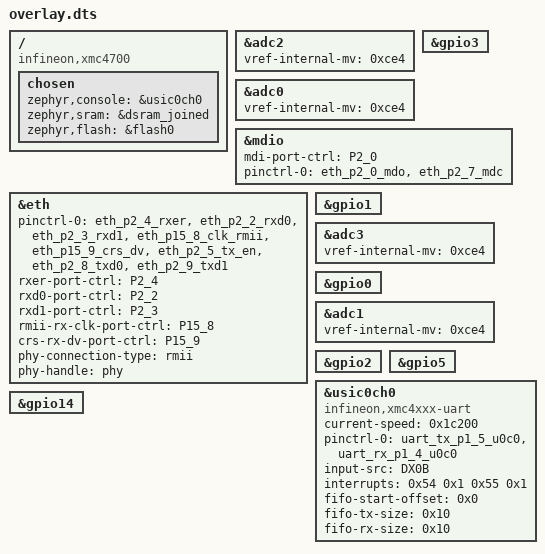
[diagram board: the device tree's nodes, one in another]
/ {
	compatible = "infineon,xmc4700", "infineon,xmc4xxx";
	chosen {
		zephyr,console = &usic0ch0;
		zephyr,sram = &dsram_joined;
		zephyr,flash = &flash0;
	};
};
&adc2{
	vref-internal-mv = < 0xce4 >;
};
&adc0{
	vref-internal-mv = < 0xce4 >;
};
&gpio3{
	status = "okay";
};
&mdio{
	status = "okay";
	mdi-port-ctrl = "P2_0";
	pinctrl-0 = < &eth_p2_0_mdo &eth_p2_7_mdc >;
	pinctrl-names = "default";
};
&eth{
	status = "okay";
	pinctrl-0 = < &eth_p2_4_rxer &eth_p2_2_rxd0 &eth_p2_3_rxd1 &eth_p15_8_clk_rmii &eth_p15_9_crs_dv &eth_p2_5_tx_en &eth_p2_8_txd0 &eth_p2_9_txd1 >;
	pinctrl-names = "default";
	rxer-port-ctrl = "P2_4";
	rxd0-port-ctrl = "P2_2";
	rxd1-port-ctrl = "P2_3";
	rmii-rx-clk-port-ctrl = "P15_8";
	crs-rx-dv-port-ctrl = "P15_9";
	phy-connection-type = "rmii";
	phy-handle = < &phy >;
};
&gpio1{
	status = "okay";
};
&adc3{
	vref-internal-mv = < 0xce4 >;
};
&gpio0{
	status = "okay";
};
&adc1{
	vref-internal-mv = < 0xce4 >;
};
&gpio2{
	status = "okay";
};
&gpio5{
	status = "okay";
};
&usic0ch0{
	status = "okay";
	compatible = "infineon,xmc4xxx-uart";
	current-speed = < 0x1c200 >;
	pinctrl-0 = < &uart_tx_p1_5_u0c0 &uart_rx_p1_4_u0c0 >;
	pinctrl-names = "default";
	input-src = "DX0B";
	interrupts = < 0x54 0x1 0x55 0x1 >;
	interrupt-names = "tx", "rx";
	fifo-start-offset = < 0x0 >;
	fifo-tx-size = < 0x10 >;
	fifo-rx-size = < 0x10 >;
};
&gpio14{
	status = "okay";
};
